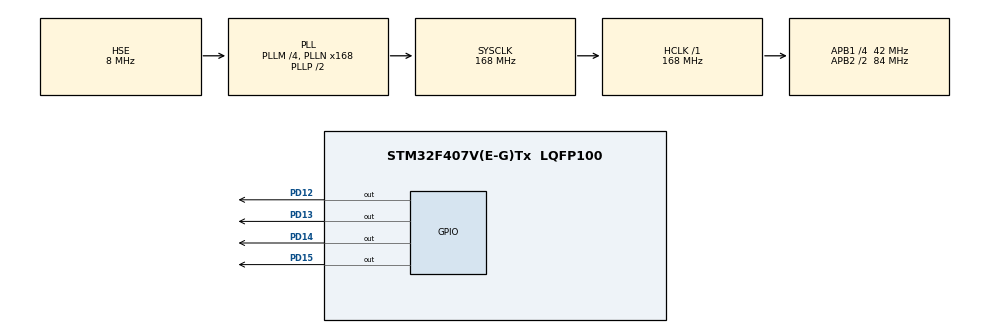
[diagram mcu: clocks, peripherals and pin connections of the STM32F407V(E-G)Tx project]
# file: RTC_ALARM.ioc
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Mcu.Family=STM32F4
Mcu.Name=STM32F407V(E-G)Tx
Mcu.Package=LQFP100
NVIC.PriorityGroup=NVIC_PRIORITYGROUP_4
NVIC.RTC_Alarm_IRQn=true\:0\:0\:false\:false\:true\:true\:true\:true
PD12.Signal=GPIO_Output
PD13.Signal=GPIO_Output
PD14.Signal=GPIO_Output
PD15.Signal=GPIO_Output
PH0-OSC_IN.Mode=HSE-External-Oscillator
PH0-OSC_IN.Signal=RCC_OSC_IN
PH1-OSC_OUT.Mode=HSE-External-Oscillator
PH1-OSC_OUT.Signal=RCC_OSC_OUT
ProjectManager.HeapSize=0x200
ProjectManager.StackSize=0x400
ProjectManager.TargetToolchain=STM32CubeIDE
RCC.48MHZClocksFreq_Value=84000000
RCC.AHBFreq_Value=168000000
RCC.APB1CLKDivider=RCC_HCLK_DIV4
RCC.APB1Freq_Value=42000000
RCC.APB1TimFreq_Value=84000000
RCC.APB2CLKDivider=RCC_HCLK_DIV2
RCC.APB2Freq_Value=84000000
RCC.APB2TimFreq_Value=168000000
RCC.CortexFreq_Value=168000000
RCC.HCLKFreq_Value=168000000
RCC.HSE_VALUE=8000000
RCC.HSI_VALUE=16000000
RCC.LSE_VALUE=32768
RCC.PLLM=4
RCC.PLLN=168
RCC.PLLSourceVirtual=RCC_PLLSOURCE_HSE
RCC.SYSCLKFreq_VALUE=168000000
RCC.SYSCLKSource=RCC_SYSCLKSOURCE_PLLCLK
RCC.VCOOutputFreq_Value=336000000
RTC.Alarm=RTC_ALARM_A
RTC.AlarmDateWeekDay=4
RTC.Date=4
RTC.Hours=21
RTC.Hours_A=21
RTC.Minutes=15
RTC.Minutes_A=16
RTC.Month=RTC_MONTH_MAY
RTC.SynchPrediv=249
RTC.WeekDay=RTC_WEEKDAY_THURSDAY
RTC.Year=23
VP_RTC_VS_RTC_Activate.Mode=RTC_Enabled
VP_RTC_VS_RTC_Alarm_A_Intern.Mode=Alarm A
VP_RTC_VS_RTC_Calendar.Mode=RTC_Calendar
board=custom

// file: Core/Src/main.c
/* USER CODE BEGIN Header */
/**
  ******************************************************************************
  * @file           : main.c
  * @brief          : Main program body
  ******************************************************************************
  * @attention
  *
  * Copyright (c) 2023 STMicroelectronics.
  * All rights reserved.
  *
  * This software is licensed under terms that can be found in the LICENSE file
  * in the root directory of this software component.
  * If no LICENSE file comes with this software, it is provided AS-IS.
  *
  ******************************************************************************
  */
/* USER CODE END Header */
#include "main.h"

 RTC_HandleTypeDef hrtc;

void SystemClock_Config(void);
static void MX_GPIO_Init(void);
static void MX_RTC_Init(void);

int main(void)
{

  /* MCU Configuration--------------------------------------------------------*/

  /* Reset of all peripherals, Initializes the Flash interface and the Systick. */
  HAL_Init();

  /* Configure the system clock */
  SystemClock_Config();

  /* Initialize all configured peripherals */
  MX_GPIO_Init();
  MX_RTC_Init();

  /* Infinite loop */
  while (1)
  {

  }
}

void SystemClock_Config(void)
{
  RCC_OscInitTypeDef RCC_OscInitStruct = {0};
  RCC_ClkInitTypeDef RCC_ClkInitStruct = {0};

  /** Configure the main internal regulator output voltage
  */
  __HAL_RCC_PWR_CLK_ENABLE();
  __HAL_PWR_VOLTAGESCALING_CONFIG(PWR_REGULATOR_VOLTAGE_SCALE1);

  /** Initializes the RCC Oscillators according to the specified parameters
  * in the RCC_OscInitTypeDef structure.
  */
  RCC_OscInitStruct.OscillatorType = RCC_OSCILLATORTYPE_LSI|RCC_OSCILLATORTYPE_HSE;
  RCC_OscInitStruct.HSEState = RCC_HSE_ON;
  RCC_OscInitStruct.LSIState = RCC_LSI_ON;
  RCC_OscInitStruct.PLL.PLLState = RCC_PLL_ON;
  RCC_OscInitStruct.PLL.PLLSource = RCC_PLLSOURCE_HSE;
  RCC_OscInitStruct.PLL.PLLM = 4;
  RCC_OscInitStruct.PLL.PLLN = 168;
  RCC_OscInitStruct.PLL.PLLP = RCC_PLLP_DIV2;
  RCC_OscInitStruct.PLL.PLLQ = 4;
  if (HAL_RCC_OscConfig(&RCC_OscInitStruct) != HAL_OK)
  {
    Error_Handler();
  }

  /** Initializes the CPU, AHB and APB buses clocks
  */
  RCC_ClkInitStruct.ClockType = RCC_CLOCKTYPE_HCLK|RCC_CLOCKTYPE_SYSCLK
                              |RCC_CLOCKTYPE_PCLK1|RCC_CLOCKTYPE_PCLK2;
  RCC_ClkInitStruct.SYSCLKSource = RCC_SYSCLKSOURCE_PLLCLK;
  RCC_ClkInitStruct.AHBCLKDivider = RCC_SYSCLK_DIV1;
  RCC_ClkInitStruct.APB1CLKDivider = RCC_HCLK_DIV4;
  RCC_ClkInitStruct.APB2CLKDivider = RCC_HCLK_DIV2;

  if (HAL_RCC_ClockConfig(&RCC_ClkInitStruct, FLASH_LATENCY_5) != HAL_OK)
  {
    Error_Handler();
  }
}

static void MX_RTC_Init(void)
{

  RTC_TimeTypeDef sTime = {0};
  RTC_DateTypeDef sDate = {0};
  RTC_AlarmTypeDef sAlarm = {0};

  /** Initialize RTC Only
  */
  hrtc.Instance = RTC;
  hrtc.Init.HourFormat = RTC_HOURFORMAT_24;
  hrtc.Init.AsynchPrediv = 127;
  hrtc.Init.SynchPrediv = 249;
  hrtc.Init.OutPut = RTC_OUTPUT_DISABLE;
  hrtc.Init.OutPutPolarity = RTC_OUTPUT_POLARITY_HIGH;
  hrtc.Init.OutPutType = RTC_OUTPUT_TYPE_OPENDRAIN;
  if (HAL_RTC_Init(&hrtc) != HAL_OK)
  {
    Error_Handler();
  }

  /** Initialize RTC and set the Time and Date
  */
  sTime.Hours = 0x21;
  sTime.Minutes = 0x15;
  sTime.Seconds = 0x0;
  sTime.DayLightSaving = RTC_DAYLIGHTSAVING_NONE;
  sTime.StoreOperation = RTC_STOREOPERATION_RESET;
  if (HAL_RTC_SetTime(&hrtc, &sTime, RTC_FORMAT_BCD) != HAL_OK)
  {
    Error_Handler();
  }
  sDate.WeekDay = RTC_WEEKDAY_THURSDAY;
  sDate.Month = RTC_MONTH_MAY;
  sDate.Date = 0x4;
  sDate.Year = 0x23;

  if (HAL_RTC_SetDate(&hrtc, &sDate, RTC_FORMAT_BCD) != HAL_OK)
  {
    Error_Handler();
  }

  /** Enable the Alarm A
  */
  sAlarm.AlarmTime.Hours = 0x21;
  sAlarm.AlarmTime.Minutes = 0x16;
  sAlarm.AlarmTime.Seconds = 0x0;
  sAlarm.AlarmTime.SubSeconds = 0x0;
  sAlarm.AlarmTime.DayLightSaving = RTC_DAYLIGHTSAVING_NONE;
  sAlarm.AlarmTime.StoreOperation = RTC_STOREOPERATION_RESET;
  sAlarm.AlarmMask = RTC_ALARMMASK_NONE;
  sAlarm.AlarmSubSecondMask = RTC_ALARMSUBSECONDMASK_ALL;
  sAlarm.AlarmDateWeekDaySel = RTC_ALARMDATEWEEKDAYSEL_DATE;
  sAlarm.AlarmDateWeekDay = 0x4;
  sAlarm.Alarm = RTC_ALARM_A;
  if (HAL_RTC_SetAlarm_IT(&hrtc, &sAlarm, RTC_FORMAT_BCD) != HAL_OK)
  {
    Error_Handler();
  }

}

static void MX_GPIO_Init(void)
{
  GPIO_InitTypeDef GPIO_InitStruct = {0};

  /* GPIO Ports Clock Enable */
  __HAL_RCC_GPIOH_CLK_ENABLE();
  __HAL_RCC_GPIOD_CLK_ENABLE();

  /*Configure GPIO pin Output Level */
  HAL_GPIO_WritePin(GPIOD, GPIO_PIN_12|GPIO_PIN_13|GPIO_PIN_14|GPIO_PIN_15, GPIO_PIN_RESET);

  /*Configure GPIO pins : PD12 PD13 PD14 PD15 */
  GPIO_InitStruct.Pin = GPIO_PIN_12|GPIO_PIN_13|GPIO_PIN_14|GPIO_PIN_15;
  GPIO_InitStruct.Mode = GPIO_MODE_OUTPUT_PP;
  GPIO_InitStruct.Pull = GPIO_NOPULL;
  GPIO_InitStruct.Speed = GPIO_SPEED_FREQ_LOW;
  HAL_GPIO_Init(GPIOD, &GPIO_InitStruct);

}

/* USER CODE BEGIN 4 */

void RTC_Alarm_IRQHandler(void)
{
  /* USER CODE BEGIN RTC_Alarm_IRQn 0 */

  /* USER CODE END RTC_Alarm_IRQn 0 */
  HAL_RTC_AlarmIRQHandler(&hrtc);
  /* USER CODE BEGIN RTC_Alarm_IRQn 1 */

  HAL_GPIO_TogglePin(GPIOD, GPIO_PIN_12 | GPIO_PIN_13 | GPIO_PIN_14 | GPIO_PIN_15);

  /* USER CODE END RTC_Alarm_IRQn 1 */
}

/* USER CODE END 4 */

void Error_Handler(void)
{
  __disable_irq();
  while (1)
  {
  }
}
